# AT91SAM9X25 register map
Vendor: Atmel; Series: SAM9X; File version: 20130207
Registers are 32-bit, read-write, reset 0x0 unless marked. A register's access mark holds for its fields unless they carry their own. Offsets are from the block's base; [hi:lo] are bit positions; {n}, {i} and the like mark numbered series; 'fields as' and 'values as' point back to an identical list.

## MATRIX — AHB Bus Matrix
Base 0xFFFFDE00; register names take the prefix MATRIX_
{0x0+4i} MCFG[{i}] (i=0..10) reset not defined — Master Configuration Register
  [2:0] ULBT — Undefined Length Burst Type
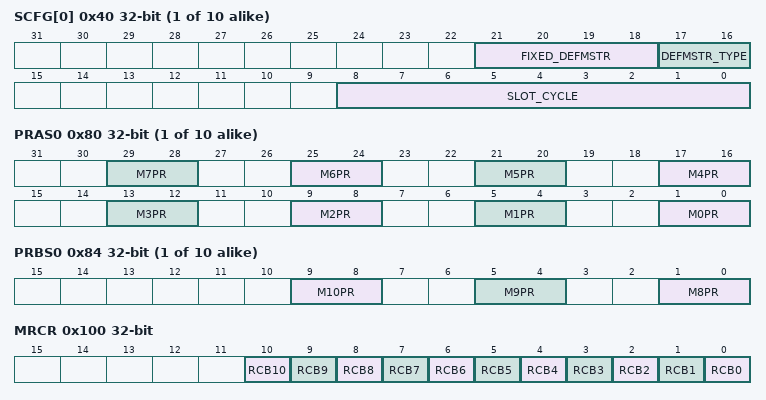
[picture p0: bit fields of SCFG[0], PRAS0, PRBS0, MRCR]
{0x40+4i} SCFG[{i}] (i=0..9) reset not defined — Slave Configuration Register
  [21:18] FIXED_DEFMSTR — Fixed Default Master
  [17:16] DEFMSTR_TYPE — Default Master Type
  [8:0] SLOT_CYCLE — Maximum Bus Grant Duration for Masters
{0x80+8i} PRAS{i} (i=0..9) — Priority Register A for Slave {i}
  [4n+1:4n] M{n}PR (n=0..7) — Master {n} Priority
{0x84+8i} PRBS{i} (i=0..9) — Priority Register B for Slave {i}
  [9:8] M10PR — Master 10 Priority
  [5:4] M9PR — Master 9 Priority
  [1:0] M8PR — Master 8 Priority
0x100 MRCR — Master Remap Control Register
  [n] RCB{n} (n=0..10) — Remap Command Bit for Master {n}
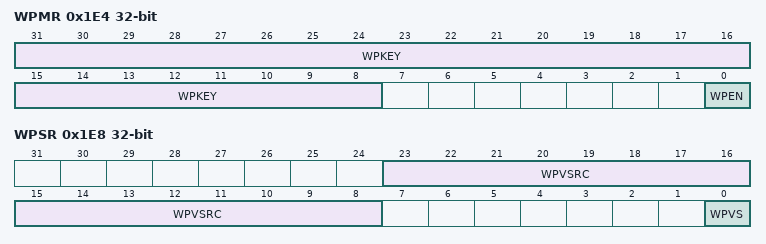
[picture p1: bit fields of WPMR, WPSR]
0x1E4 WPMR — Write Protect Mode Register
  [31:8] WPKEY — Write Protect KEY (Write-only)
  [0] WPEN — Write Protect ENable
0x1E8 WPSR ro — Write Protect Status Register
  [23:8] WPVSRC — Write Protect Violation Source
  [0] WPVS — Write Protect Violation Status

## PMECC — Programmable Multibit Error Corrected Code Controller
Base 0xFFFFE000; register names take the prefix PMECC_
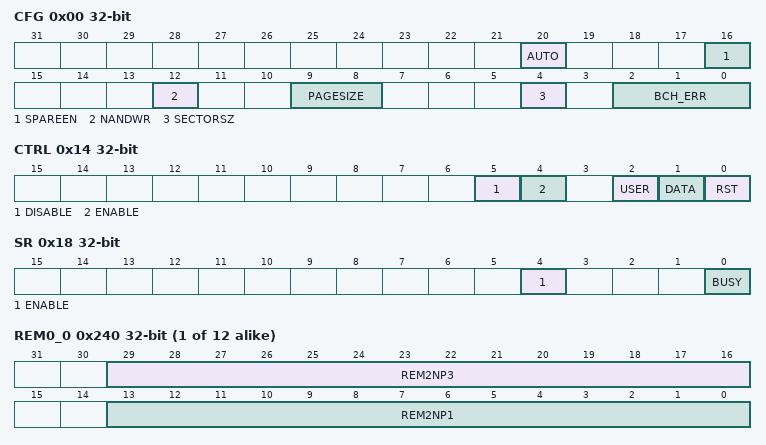
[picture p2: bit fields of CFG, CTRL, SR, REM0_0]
0x00 CFG — PMECC Configuration Register
  [20] AUTO — Automatic Mode Enable
  [16] SPAREEN — Spare Enable
  [12] NANDWR — NAND Write Access
  [9:8] PAGESIZE — Number of Sectors in the Page
    0=PAGESIZE_1SEC (1 sector for main area (512 or 1024 bytes)); 1=PAGESIZE_2SEC (2 sectors for main area (1024 or 2048 bytes)); 2=PAGESIZE_4SEC (4 sectors for main area (2048 or 4096 bytes)); 3=PAGESIZE_8SEC (8 errors for main area (4096 or 8192 bytes))
  [4] SECTORSZ — Sector Size
  [2:0] BCH_ERR — Error Correct Capability
    0=2 errors; 1=4 errors; 2=8 errors; 3=12 errors; 4=24 errors
0x04 SAREA — PMECC Spare Area Size Register
  [8:0] SPARESIZE — Spare Area Size
0x08 SADDR — PMECC Start Address Register
  [8:0] STARTADDR — ECC Area Start Address (byte oriented address)
0x0C EADDR — PMECC End Address Register
  [8:0] ENDADDR — ECC Area End Address (byte oriented address)
0x10 CLK — PMECC Clock Control Register
  [2:0] CLKCTRL — Clock Control Register
0x14 CTRL wo — PMECC Control Register
  [5] DISABLE — PMECC Module Disable
  [4] ENABLE — PMECC Module Enable
  [2] USER — Start a User Mode Phase
  [1] DATA — Start a Data Phase
  [0] RST — Reset the PMECC Module
0x18 SR ro — PMECC Status Register
  [4] ENABLE — PMECC Module Status
  [0] BUSY — The Kernel of the PMECC is Busy
0x1C IER wo — PMECC Interrupt Enable register
  [0] ERRIE — Error Interrupt Enable
0x20 IDR wo reset not defined — PMECC Interrupt Disable Register
  [0] ERRID — Error Interrupt Disable
0x24 IMR ro — PMECC Interrupt Mask Register
  [0] ERRIM — Error Interrupt Enable
0x28 ISR ro — PMECC Interrupt Status Register
  [7:0] ERRIS — Error Interrupt Status Register
{0x40+4i} ECC{i}_0 ro (i=0..10) — PMECC ECC {i} Register (sec_num = 0)
  [31:0] ECC — BCH Redundancy
{0x80+4i} ECC{i}_1 ro (i=0..10) — PMECC ECC {i} Register (sec_num = 1)
  [31:0] ECC — BCH Redundancy
{0xC0+4i} ECC{i}_2 ro (i=0..10) — PMECC ECC {i} Register (sec_num = 2)
  [31:0] ECC — BCH Redundancy
{0x100+4i} ECC{i}_3 ro (i=0..10) — PMECC ECC {i} Register (sec_num = 3)
  [31:0] ECC — BCH Redundancy
{0x140+4i} ECC{i}_4 ro (i=0..10) — PMECC ECC {i} Register (sec_num = 4)
  [31:0] ECC — BCH Redundancy
{0x180+4i} ECC{i}_5 ro (i=0..10) — PMECC ECC {i} Register (sec_num = 5)
  [31:0] ECC — BCH Redundancy
{0x1C0+4i} ECC{i}_6 ro (i=0..10) — PMECC ECC {i} Register (sec_num = 6)
  [31:0] ECC — BCH Redundancy
{0x200+4i} ECC{i}_7 ro (i=0..10) — PMECC ECC {i} Register (sec_num = 7)
  [31:0] ECC — BCH Redundancy
{0x240+4i} REM{i}_0 ro (i=0..11) — PMECC REM {i} Register (sec_num = 0)
  [29:16] REM2NP3 — BCH Remainder 2 * N + 3
  [13:0] REM2NP1 — BCH Remainder 2 * N + 1
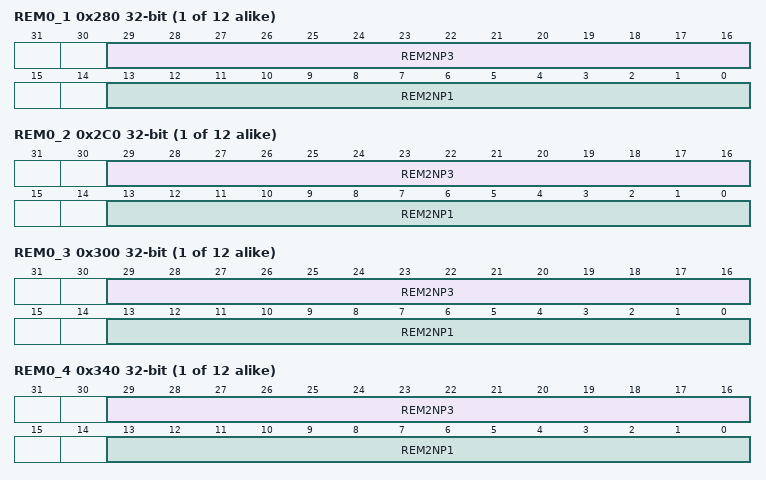
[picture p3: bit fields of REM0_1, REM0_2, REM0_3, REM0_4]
{0x280+4i} REM{i}_1 ro (i=0..11) — PMECC REM {i} Register (sec_num = 1)
  fields as REM0_0
{0x2C0+4i} REM{i}_2 ro (i=0..11) — PMECC REM {i} Register (sec_num = 2)
  fields as REM0_0
{0x300+4i} REM{i}_3 ro (i=0..11) — PMECC REM {i} Register (sec_num = 3)
  fields as REM0_0
{0x340+4i} REM{i}_4 ro (i=0..11) — PMECC REM {i} Register (sec_num = 4)
  fields as REM0_0
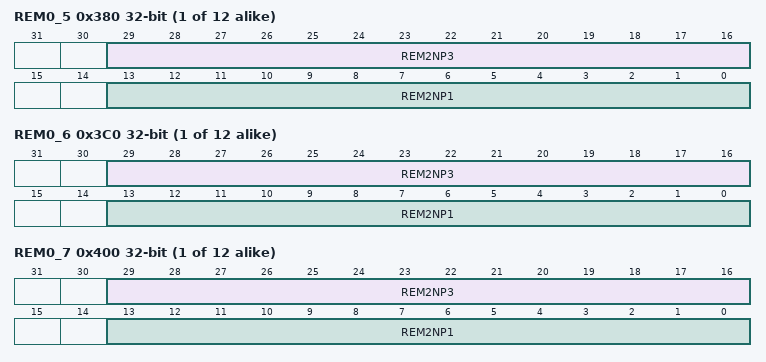
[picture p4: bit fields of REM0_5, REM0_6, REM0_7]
{0x380+4i} REM{i}_5 ro (i=0..11) — PMECC REM {i} Register (sec_num = 5)
  fields as REM0_0
{0x3C0+4i} REM{i}_6 ro (i=0..11) — PMECC REM {i} Register (sec_num = 6)
  fields as REM0_0
{0x400+4i} REM{i}_7 ro (i=0..11) — PMECC REM {i} Register (sec_num = 7)
  fields as REM0_0
